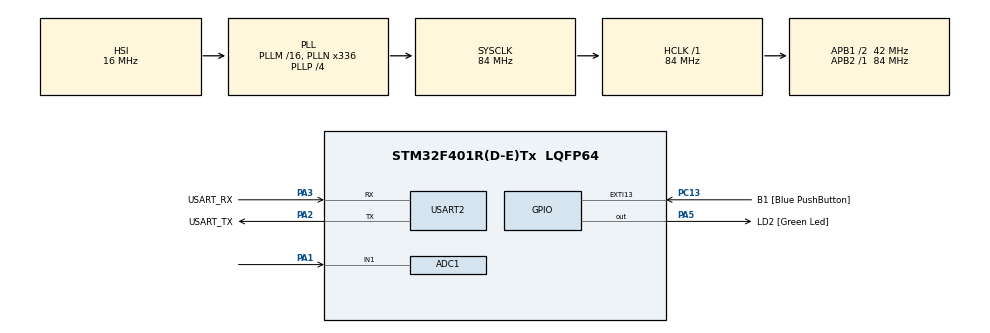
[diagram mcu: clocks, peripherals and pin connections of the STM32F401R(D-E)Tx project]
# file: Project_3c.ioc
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ADC1.Channel-0\#ChannelRegularConversion=ADC_CHANNEL_1
ADC1.Channel-1\#ChannelRegularConversion=ADC_CHANNEL_TEMPSENSOR
ADC1.Channel-2\#ChannelRegularConversion=ADC_CHANNEL_VREFINT
ADC1.DMAContinuousRequests=ENABLE
ADC1.ExternalTrigConv=ADC_EXTERNALTRIGCONV_T3_TRGO
ADC1.NbrOfConversion=3
ADC1.NbrOfConversionFlag=1
ADC1.Rank-0\#ChannelRegularConversion=1
ADC1.Rank-1\#ChannelRegularConversion=2
ADC1.Rank-2\#ChannelRegularConversion=3
ADC1.SamplingTime-0\#ChannelRegularConversion=ADC_SAMPLETIME_480CYCLES
ADC1.SamplingTime-1\#ChannelRegularConversion=ADC_SAMPLETIME_480CYCLES
ADC1.SamplingTime-2\#ChannelRegularConversion=ADC_SAMPLETIME_480CYCLES
ADC1.master=1
Dma.ADC1.0.Direction=DMA_PERIPH_TO_MEMORY
Dma.ADC1.0.FIFOMode=DMA_FIFOMODE_DISABLE
Dma.ADC1.0.Instance=DMA2_Stream0
Dma.ADC1.0.MemDataAlignment=DMA_MDATAALIGN_WORD
Dma.ADC1.0.MemInc=DMA_MINC_ENABLE
Dma.ADC1.0.Mode=DMA_CIRCULAR
Dma.ADC1.0.PeriphDataAlignment=DMA_PDATAALIGN_WORD
Dma.ADC1.0.PeriphInc=DMA_PINC_DISABLE
Dma.ADC1.0.Priority=DMA_PRIORITY_LOW
Dma.Request0=ADC1
Mcu.Family=STM32F4
Mcu.Name=STM32F401R(D-E)Tx
Mcu.Package=LQFP64
NVIC.ADC_IRQn=true\:0\:0\:false\:false\:true\:true\:true
NVIC.DMA2_Stream0_IRQn=true\:0\:0\:false\:false\:true\:false\:true
NVIC.PriorityGroup=NVIC_PRIORITYGROUP_0
PA1.Signal=ADCx_IN1
PA13.GPIO_Label=TMS
PA13.Mode=Serial_Wire
PA13.Signal=SYS_JTMS-SWDIO
PA14.GPIO_Label=TCK
PA14.Mode=Serial_Wire
PA14.Signal=SYS_JTCK-SWCLK
PA2.GPIO_Label=USART_TX
PA2.GPIO_Mode=GPIO_MODE_AF_PP
PA2.GPIO_PuPd=GPIO_NOPULL
PA2.GPIO_Speed=GPIO_SPEED_FREQ_LOW
PA2.Mode=Asynchronous
PA2.Signal=USART2_TX
PA3.GPIO_Label=USART_RX
PA3.GPIO_Mode=GPIO_MODE_AF_PP
PA3.GPIO_PuPd=GPIO_NOPULL
PA3.GPIO_Speed=GPIO_SPEED_FREQ_LOW
PA3.Mode=Asynchronous
PA3.Signal=USART2_RX
PA5.GPIO_Label=LD2 [Green Led]
PA5.GPIO_Mode=GPIO_MODE_OUTPUT_PP
PA5.GPIO_PuPd=GPIO_NOPULL
PA5.GPIO_Speed=GPIO_SPEED_FREQ_LOW
PA5.Signal=GPIO_Output
PB3.GPIO_Label=SWO
PB3.Signal=SYS_JTDO-SWO
PC13-ANTI_TAMP.GPIO_Label=B1 [Blue PushButton]
PC13-ANTI_TAMP.GPIO_ModeDefaultEXTI=GPIO_MODE_IT_FALLING
PC13-ANTI_TAMP.GPIO_PuPd=GPIO_NOPULL
PC13-ANTI_TAMP.Signal=GPXTI13
PC14-OSC32_IN.Mode=LSE-External-Oscillator
PC14-OSC32_IN.Signal=RCC_OSC32_IN
PC15-OSC32_OUT.Mode=LSE-External-Oscillator
PC15-OSC32_OUT.Signal=RCC_OSC32_OUT
PH0\ -\ OSC_IN.Mode=HSE-External-Clock-Source
PH0\ -\ OSC_IN.Signal=RCC_OSC_IN
PH1\ -\ OSC_OUT.Mode=HSE-External-Clock-Source
PH1\ -\ OSC_OUT.Signal=RCC_OSC_OUT
ProjectManager.HeapSize=0x200
ProjectManager.StackSize=0x400
ProjectManager.TargetToolchain=STM32CubeIDE
RCC.48MHZClocksFreq_Value=48000000
RCC.AHBFreq_Value=84000000
RCC.APB1CLKDivider=RCC_HCLK_DIV2
RCC.APB1Freq_Value=42000000
RCC.APB1TimFreq_Value=84000000
RCC.APB2Freq_Value=84000000
RCC.APB2TimFreq_Value=84000000
RCC.CortexFreq_Value=84000000
RCC.HCLKFreq_Value=84000000
RCC.HSE_VALUE=8000000
RCC.HSI_VALUE=16000000
RCC.PLLN=336
RCC.PLLP=RCC_PLLP_DIV4
RCC.PLLQ=7
RCC.SYSCLKFreq_VALUE=84000000
RCC.SYSCLKSource=RCC_SYSCLKSOURCE_PLLCLK
RCC.VCOOutputFreq_Value=336000000
SH.ADCx_IN1.0=ADC1_IN1,IN1
TIM3.Period=2000-1
TIM3.Prescaler=42000-1
TIM3.TIM_MasterOutputTrigger=TIM_TRGO_UPDATE
USART2.VirtualMode=VM_ASYNC
VP_ADC1_TempSens_Input.Mode=IN-TempSens
VP_ADC1_Vref_Input.Mode=IN-Vrefint
VP_TIM3_VS_ClockSourceINT.Mode=Internal
board=NUCLEO-F401RE

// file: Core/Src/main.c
/* USER CODE BEGIN Header */
/**
  ******************************************************************************
  * @file           : main.c
  * @brief          : Main program body
  ******************************************************************************
  * @attention
  *
  * <h2><center>&copy; Copyright (c) 2021 STMicroelectronics.
  * All rights reserved.</center></h2>
  *
  * This software component is licensed by ST under BSD 3-Clause license,
  * the "License"; You may not use this file except in compliance with the
  * License. You may obtain a copy of the License at:
  *                        opensource.org/licenses/BSD-3-Clause
  *
  ******************************************************************************
  */
/* USER CODE END Header */
#include "main.h"

/* USER CODE BEGIN Includes */
#include "string.h"
#include "stdio.h"
/* USER CODE END Includes */

/* USER CODE BEGIN PD */
#define LENGTH 3
/* USER CODE END PD */

ADC_HandleTypeDef hadc1;
DMA_HandleTypeDef hdma_adc1;

TIM_HandleTypeDef htim3;

UART_HandleTypeDef huart2;

/* USER CODE BEGIN PV */
uint32_t array[3];
/* USER CODE END PV */

void SystemClock_Config(void);
static void MX_GPIO_Init(void);
static void MX_DMA_Init(void);
static void MX_USART2_UART_Init(void);
static void MX_ADC1_Init(void);
static void MX_TIM3_Init(void);

int main(void)
{

  /* MCU Configuration--------------------------------------------------------*/

  /* Reset of all peripherals, Initializes the Flash interface and the Systick. */
  HAL_Init();

  /* Configure the system clock */
  SystemClock_Config();

  /* Initialize all configured peripherals */
  MX_GPIO_Init();
  MX_DMA_Init();
  MX_USART2_UART_Init();
  MX_ADC1_Init();
  MX_TIM3_Init();
  /* USER CODE BEGIN 2 */
  HAL_TIM_Base_Start(&htim3);
  HAL_ADC_Start_DMA(&hadc1, array, LENGTH);
  /* USER CODE END 2 */

  /* Infinite loop */
  while (1)
  {

  }
}

void SystemClock_Config(void)
{
  RCC_OscInitTypeDef RCC_OscInitStruct = {0};
  RCC_ClkInitTypeDef RCC_ClkInitStruct = {0};

  /** Configure the main internal regulator output voltage
  */
  __HAL_RCC_PWR_CLK_ENABLE();
  __HAL_PWR_VOLTAGESCALING_CONFIG(PWR_REGULATOR_VOLTAGE_SCALE2);
  /** Initializes the RCC Oscillators according to the specified parameters
  * in the RCC_OscInitTypeDef structure.
  */
  RCC_OscInitStruct.OscillatorType = RCC_OSCILLATORTYPE_HSI;
  RCC_OscInitStruct.HSIState = RCC_HSI_ON;
  RCC_OscInitStruct.HSICalibrationValue = RCC_HSICALIBRATION_DEFAULT;
  RCC_OscInitStruct.PLL.PLLState = RCC_PLL_ON;
  RCC_OscInitStruct.PLL.PLLSource = RCC_PLLSOURCE_HSI;
  RCC_OscInitStruct.PLL.PLLM = 16;
  RCC_OscInitStruct.PLL.PLLN = 336;
  RCC_OscInitStruct.PLL.PLLP = RCC_PLLP_DIV4;
  RCC_OscInitStruct.PLL.PLLQ = 7;
  if (HAL_RCC_OscConfig(&RCC_OscInitStruct) != HAL_OK)
  {
    Error_Handler();
  }
  /** Initializes the CPU, AHB and APB buses clocks
  */
  RCC_ClkInitStruct.ClockType = RCC_CLOCKTYPE_HCLK|RCC_CLOCKTYPE_SYSCLK
                              |RCC_CLOCKTYPE_PCLK1|RCC_CLOCKTYPE_PCLK2;
  RCC_ClkInitStruct.SYSCLKSource = RCC_SYSCLKSOURCE_PLLCLK;
  RCC_ClkInitStruct.AHBCLKDivider = RCC_SYSCLK_DIV1;
  RCC_ClkInitStruct.APB1CLKDivider = RCC_HCLK_DIV2;
  RCC_ClkInitStruct.APB2CLKDivider = RCC_HCLK_DIV1;

  if (HAL_RCC_ClockConfig(&RCC_ClkInitStruct, FLASH_LATENCY_2) != HAL_OK)
  {
    Error_Handler();
  }
}

static void MX_ADC1_Init(void)
{

  ADC_ChannelConfTypeDef sConfig = {0};

  /** Configure the global features of the ADC (Clock, Resolution, Data Alignment and number of conversion)
  */
  hadc1.Instance = ADC1;
  hadc1.Init.ClockPrescaler = ADC_CLOCK_SYNC_PCLK_DIV4;
  hadc1.Init.Resolution = ADC_RESOLUTION_12B;
  hadc1.Init.ScanConvMode = ENABLE;
  hadc1.Init.ContinuousConvMode = DISABLE;
  hadc1.Init.DiscontinuousConvMode = DISABLE;
  hadc1.Init.ExternalTrigConvEdge = ADC_EXTERNALTRIGCONVEDGE_RISING;
  hadc1.Init.ExternalTrigConv = ADC_EXTERNALTRIGCONV_T3_TRGO;
  hadc1.Init.DataAlign = ADC_DATAALIGN_RIGHT;
  hadc1.Init.NbrOfConversion = 3;
  hadc1.Init.DMAContinuousRequests = ENABLE;
  hadc1.Init.EOCSelection = ADC_EOC_SINGLE_CONV;
  if (HAL_ADC_Init(&hadc1) != HAL_OK)
  {
    Error_Handler();
  }
  /** Configure for the selected ADC regular channel its corresponding rank in the sequencer and its sample time.
  */
  sConfig.Channel = ADC_CHANNEL_1;
  sConfig.Rank = 1;
  sConfig.SamplingTime = ADC_SAMPLETIME_480CYCLES;
  if (HAL_ADC_ConfigChannel(&hadc1, &sConfig) != HAL_OK)
  {
    Error_Handler();
  }
  /** Configure for the selected ADC regular channel its corresponding rank in the sequencer and its sample time.
  */
  sConfig.Channel = ADC_CHANNEL_TEMPSENSOR;
  sConfig.Rank = 2;
  if (HAL_ADC_ConfigChannel(&hadc1, &sConfig) != HAL_OK)
  {
    Error_Handler();
  }
  /** Configure for the selected ADC regular channel its corresponding rank in the sequencer and its sample time.
  */
  sConfig.Channel = ADC_CHANNEL_VREFINT;
  sConfig.Rank = 3;
  if (HAL_ADC_ConfigChannel(&hadc1, &sConfig) != HAL_OK)
  {
    Error_Handler();
  }

}

static void MX_TIM3_Init(void)
{

  TIM_ClockConfigTypeDef sClockSourceConfig = {0};
  TIM_MasterConfigTypeDef sMasterConfig = {0};

  htim3.Instance = TIM3;
  htim3.Init.Prescaler = 42000-1;
  htim3.Init.CounterMode = TIM_COUNTERMODE_UP;
  htim3.Init.Period = 2000-1;
  htim3.Init.ClockDivision = TIM_CLOCKDIVISION_DIV1;
  htim3.Init.AutoReloadPreload = TIM_AUTORELOAD_PRELOAD_DISABLE;
  if (HAL_TIM_Base_Init(&htim3) != HAL_OK)
  {
    Error_Handler();
  }
  sClockSourceConfig.ClockSource = TIM_CLOCKSOURCE_INTERNAL;
  if (HAL_TIM_ConfigClockSource(&htim3, &sClockSourceConfig) != HAL_OK)
  {
    Error_Handler();
  }
  sMasterConfig.MasterOutputTrigger = TIM_TRGO_UPDATE;
  sMasterConfig.MasterSlaveMode = TIM_MASTERSLAVEMODE_DISABLE;
  if (HAL_TIMEx_MasterConfigSynchronization(&htim3, &sMasterConfig) != HAL_OK)
  {
    Error_Handler();
  }

}

static void MX_USART2_UART_Init(void)
{

  huart2.Instance = USART2;
  huart2.Init.BaudRate = 115200;
  huart2.Init.WordLength = UART_WORDLENGTH_8B;
  huart2.Init.StopBits = UART_STOPBITS_1;
  huart2.Init.Parity = UART_PARITY_NONE;
  huart2.Init.Mode = UART_MODE_TX_RX;
  huart2.Init.HwFlowCtl = UART_HWCONTROL_NONE;
  huart2.Init.OverSampling = UART_OVERSAMPLING_16;
  if (HAL_UART_Init(&huart2) != HAL_OK)
  {
    Error_Handler();
  }

}

static void MX_DMA_Init(void)
{

  /* DMA controller clock enable */
  __HAL_RCC_DMA2_CLK_ENABLE();

  /* DMA interrupt init */
  /* DMA2_Stream0_IRQn interrupt configuration */
  HAL_NVIC_SetPriority(DMA2_Stream0_IRQn, 0, 0);
  HAL_NVIC_EnableIRQ(DMA2_Stream0_IRQn);

}

static void MX_GPIO_Init(void)
{
  GPIO_InitTypeDef GPIO_InitStruct = {0};

  /* GPIO Ports Clock Enable */
  __HAL_RCC_GPIOC_CLK_ENABLE();
  __HAL_RCC_GPIOH_CLK_ENABLE();
  __HAL_RCC_GPIOA_CLK_ENABLE();
  __HAL_RCC_GPIOB_CLK_ENABLE();

  /*Configure GPIO pin Output Level */
  HAL_GPIO_WritePin(LD2_GPIO_Port, LD2_Pin, GPIO_PIN_RESET);

  /*Configure GPIO pin : B1_Pin */
  GPIO_InitStruct.Pin = B1_Pin;
  GPIO_InitStruct.Mode = GPIO_MODE_IT_FALLING;
  GPIO_InitStruct.Pull = GPIO_NOPULL;
  HAL_GPIO_Init(B1_GPIO_Port, &GPIO_InitStruct);

  /*Configure GPIO pin : LD2_Pin */
  GPIO_InitStruct.Pin = LD2_Pin;
  GPIO_InitStruct.Mode = GPIO_MODE_OUTPUT_PP;
  GPIO_InitStruct.Pull = GPIO_NOPULL;
  GPIO_InitStruct.Speed = GPIO_SPEED_FREQ_LOW;
  HAL_GPIO_Init(LD2_GPIO_Port, &GPIO_InitStruct);

}

/* USER CODE BEGIN 4 */
void HAL_ADC_ConvCpltCallback(ADC_HandleTypeDef* hadc)
{
	float pot = array[0]*3.3/4096;
	float vtemp = array[1]*3.3/4096;
	float ref = (1.21*4096)/array[2];

	float temp = (vtemp - 0.76)/0.0025 + 25;

	char str[50];
	snprintf(str, sizeof(str), "Pot: %1.3fV\r\nSup: %1.3fV\r\nTemp: %2.1f°C\r\n", pot, ref, temp);
	HAL_UART_Transmit(&huart2, str, strlen(str), 1000);
}
/* USER CODE END 4 */

void Error_Handler(void)
{
}

/************************ (C) COPYRIGHT STMicroelectronics *****END OF FILE****/
